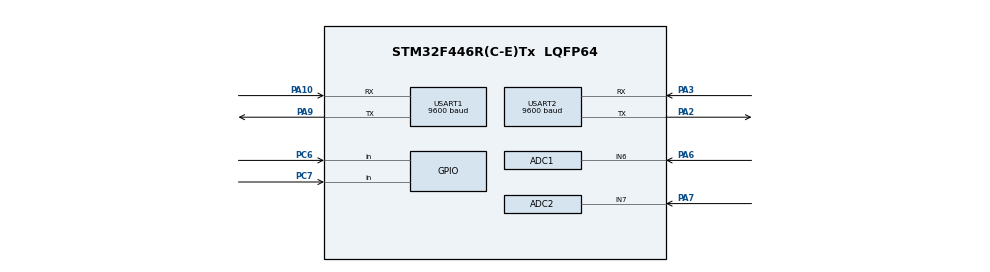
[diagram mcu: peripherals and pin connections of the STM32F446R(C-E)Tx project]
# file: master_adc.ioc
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ADC1.Channel-0\#ChannelRegularConversion=ADC_CHANNEL_6
ADC1.NbrOfConversionFlag=1
ADC1.Rank-0\#ChannelRegularConversion=1
ADC1.Resolution=ADC_RESOLUTION_8B
ADC1.SamplingTime-0\#ChannelRegularConversion=ADC_SAMPLETIME_3CYCLES
ADC1.master=1
ADC2.Channel-0\#ChannelRegularConversion=ADC_CHANNEL_7
ADC2.NbrOfConversionFlag=1
ADC2.Rank-0\#ChannelRegularConversion=1
ADC2.Resolution=ADC_RESOLUTION_8B
ADC2.SamplingTime-0\#ChannelRegularConversion=ADC_SAMPLETIME_3CYCLES
Mcu.Family=STM32F4
Mcu.Name=STM32F446R(C-E)Tx
Mcu.Package=LQFP64
NVIC.PriorityGroup=NVIC_PRIORITYGROUP_4
NVIC.USART1_IRQn=true\:0\:0\:false\:false\:true\:true\:true\:true
PA10.Mode=Asynchronous
PA10.Signal=USART1_RX
PA13.Mode=Serial_Wire
PA13.Signal=SYS_JTMS-SWDIO
PA14.Mode=Serial_Wire
PA14.Signal=SYS_JTCK-SWCLK
PA2.Mode=Asynchronous
PA2.Signal=USART2_TX
PA3.Mode=Asynchronous
PA3.Signal=USART2_RX
PA6.Signal=ADCx_IN6
PA7.Signal=ADCx_IN7
PA9.Mode=Asynchronous
PA9.Signal=USART1_TX
PC6.Signal=GPIO_Input
PC7.Signal=GPIO_Input
ProjectManager.HeapSize=0x200
ProjectManager.StackSize=0x400
ProjectManager.TargetToolchain=STM32CubeIDE
RCC.CortexFreq_Value=16000000
RCC.USBFreq_Value=96000000
RCC.VCOOutputFreq_Value=192000000
SH.ADCx_IN6.0=ADC1_IN6,IN6
SH.ADCx_IN7.0=ADC2_IN7,IN7
USART1.BaudRate=9600
USART1.VirtualMode=VM_ASYNC
USART2.BaudRate=9600
USART2.VirtualMode=VM_ASYNC
board=custom

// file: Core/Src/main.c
/* USER CODE BEGIN Header */
/**
  ******************************************************************************
  * @file           : main.c
  * @brief          : Main program body
  ******************************************************************************
  * @attention
  *
  * Copyright (c) 2023 STMicroelectronics.
  * All rights reserved.
  *
  * This software is licensed under terms that can be found in the LICENSE file
  * in the root directory of this software component.
  * If no LICENSE file comes with this software, it is provided AS-IS.
  *
  ******************************************************************************
  */
/* USER CODE END Header */
#include "main.h"
#include "adc.h"
#include "usart.h"
#include "gpio.h"
#include "stdio.h"

/* USER CODE BEGIN PD */
#define BUFFER_LEN 2
/* USER CODE END PD */

/* USER CODE BEGIN PV */
uint8_t TX_BUFFER[BUFFER_LEN] = {0};
/* USER CODE END PV */

void SystemClock_Config(void);
/* USER CODE BEGIN PFP */
void HAL_UART_TxCpltCallback(UART_HandleTypeDef *huart)
{
	if(huart->Instance == huart1.Instance)
	{
      HAL_UART_Transmit_IT(&huart1, TX_BUFFER, sizeof (TX_BUFFER));
	}
}

/* USER CODE END PFP */

int main(void)
{

  /* MCU Configuration--------------------------------------------------------*/

  /* Reset of all peripherals, Initializes the Flash interface and the Systick. */
  HAL_Init();

  /* Configure the system clock */
  SystemClock_Config();

  /* Initialize all configured peripherals */
  MX_GPIO_Init();
  MX_ADC1_Init();
  MX_USART1_UART_Init();
  MX_ADC2_Init();
  MX_USART2_UART_Init();

  /* Infinite loop */
  /* USER CODE BEGIN WHILE */
  char msg[80];
  while (1)
  {
	  HAL_ADC_Start(&hadc1);
	  HAL_ADC_PollForConversion(&hadc1, 100);

	  HAL_ADC_Start(&hadc2);
	  HAL_ADC_PollForConversion(&hadc2, 100);

	  TX_BUFFER[0]=HAL_ADC_GetValue(&hadc1);
	  TX_BUFFER[1]=HAL_ADC_GetValue(&hadc2);

 	 sprintf(msg, "%d %d\r\n\n", TX_BUFFER[0],TX_BUFFER[1]);
 	 HAL_UART_Transmit(&huart2, (uint8_t*) msg, strlen(msg), HAL_MAX_DELAY);
 	 HAL_Delay(100);

	  HAL_UART_Transmit(&huart1, TX_BUFFER, sizeof (TX_BUFFER),100);
  }
  /* USER CODE END 3 */
}

void SystemClock_Config(void)
{
  RCC_OscInitTypeDef RCC_OscInitStruct = {0};
  RCC_ClkInitTypeDef RCC_ClkInitStruct = {0};

  /** Configure the main internal regulator output voltage
  */
  __HAL_RCC_PWR_CLK_ENABLE();
  __HAL_PWR_VOLTAGESCALING_CONFIG(PWR_REGULATOR_VOLTAGE_SCALE3);

  /** Initializes the RCC Oscillators according to the specified parameters
  * in the RCC_OscInitTypeDef structure.
  */
  RCC_OscInitStruct.OscillatorType = RCC_OSCILLATORTYPE_HSI;
  RCC_OscInitStruct.HSIState = RCC_HSI_ON;
  RCC_OscInitStruct.HSICalibrationValue = RCC_HSICALIBRATION_DEFAULT;
  RCC_OscInitStruct.PLL.PLLState = RCC_PLL_NONE;
  if (HAL_RCC_OscConfig(&RCC_OscInitStruct) != HAL_OK)
  {
    Error_Handler();
  }

  /** Initializes the CPU, AHB and APB buses clocks
  */
  RCC_ClkInitStruct.ClockType = RCC_CLOCKTYPE_HCLK|RCC_CLOCKTYPE_SYSCLK
                              |RCC_CLOCKTYPE_PCLK1|RCC_CLOCKTYPE_PCLK2;
  RCC_ClkInitStruct.SYSCLKSource = RCC_SYSCLKSOURCE_HSI;
  RCC_ClkInitStruct.AHBCLKDivider = RCC_SYSCLK_DIV1;
  RCC_ClkInitStruct.APB1CLKDivider = RCC_HCLK_DIV1;
  RCC_ClkInitStruct.APB2CLKDivider = RCC_HCLK_DIV1;

  if (HAL_RCC_ClockConfig(&RCC_ClkInitStruct, FLASH_LATENCY_0) != HAL_OK)
  {
    Error_Handler();
  }
}

void Error_Handler(void)
{
  __disable_irq();
  while (1)
  {
  }
}
